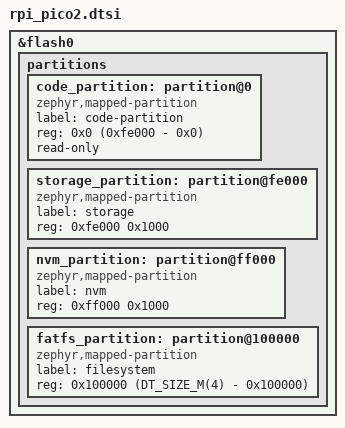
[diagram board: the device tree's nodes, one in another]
/* RP2350 UF2-native layout (no mcuboot): applied to the application image only.
 *
 * RP2350 boots from its own second-stage bootloader (UF2), so there is no
 * mcuboot domain. The fork still owns this layout so CircuitPython, Arduino,
 * and Wippersnapper share the same code/nvm/storage/filesystem placement.
 * Flash is 4 MB on the Raspberry Pi Pico 2. RP2350 has no separate
 * second_stage_bootloader partition (the bootloader lives below 0x0 in the
 * bootrom), so code starts at 0x0.
 *
 * The non-W Picos (1020 KB code) and W Picos (1532 KB code to fit the CYW43
 * blob) have different layouts; the W variant is in dts/rpi_pico2_w.dtsi and
 * sysbuild.cmake picks the one whose key matches the Zephyr board id first.
 */
&flash0 {
	partitions {
		#address-cells = <1>;
		#size-cells = <1>;

		code_partition: partition@0 {
			compatible = "zephyr,mapped-partition";
			label = "code-partition";
			reg = <0x0 (0xfe000 - 0x0)>;
			read-only;
		};

		storage_partition: partition@fe000 {
			compatible = "zephyr,mapped-partition";
			label = "storage";
			reg = <0xfe000 0x1000>;
		};

		nvm_partition: partition@ff000 {
			compatible = "zephyr,mapped-partition";
			label = "nvm";
			reg = <0xff000 0x1000>;
		};

		fatfs_partition: partition@100000 {
			compatible = "zephyr,mapped-partition";
			label = "filesystem";
			reg = <0x100000 (DT_SIZE_M(4) - 0x100000)>;
		};
	};
};
